CM_ "AUTOGENERATED FILE, DO NOT EDIT"
CM_ "Imported file _honda_2017.dbc starts here"
VERSION ""

NS_ :

BU_: EBCM ADAS PCM EPS VSA SCM BDY XXX EPB EON

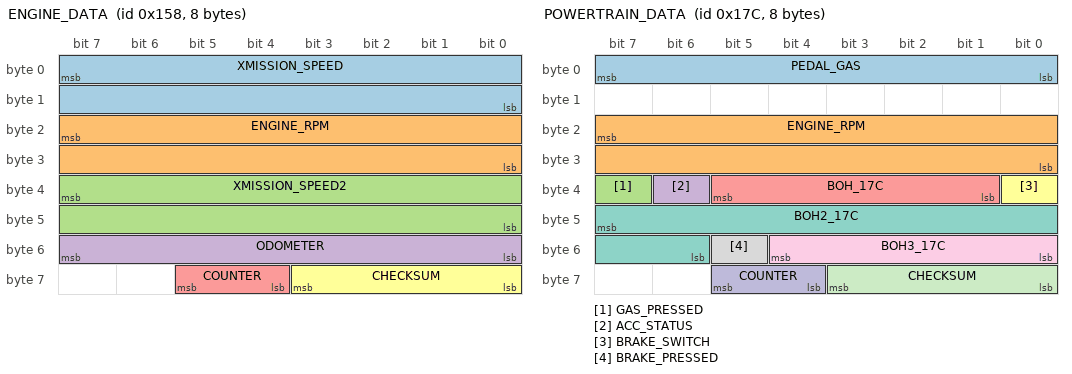
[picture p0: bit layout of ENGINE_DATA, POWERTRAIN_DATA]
BO_ 344 ENGINE_DATA: 8 PCM
 SG_ XMISSION_SPEED : 7|16@0+ (0.01,0) [0|250] "kph" EON
 SG_ ENGINE_RPM : 23|16@0+ (1,0) [0|15000] "rpm" EON
 SG_ XMISSION_SPEED2 : 39|16@0+ (0.01,0) [0|250] "kph" EON
 SG_ ODOMETER : 55|8@0+ (0.010588,0) [0|255] "km" XXX
 SG_ COUNTER : 61|2@0+ (1,0) [0|3] "" EON
 SG_ CHECKSUM : 59|4@0+ (1,0) [0|15] "" EON

BO_ 380 POWERTRAIN_DATA: 8 PCM
 SG_ PEDAL_GAS : 7|8@0+ (1,0) [0|255] "" EON
 SG_ ENGINE_RPM : 23|16@0+ (1,0) [0|15000] "rpm" EON
 SG_ GAS_PRESSED : 39|1@0+ (1,0) [0|1] "" EON
 SG_ ACC_STATUS : 38|1@0+ (1,0) [0|1] "rpm" EON
 SG_ BOH_17C : 37|5@0+ (1,0) [0|1] "rpm" EON
 SG_ BRAKE_SWITCH : 32|1@0+ (1,0) [0|1] "rpm" EON
 SG_ BOH2_17C : 47|10@0+ (1,0) [0|1] "rpm" EON
 SG_ BRAKE_PRESSED : 53|1@0+ (1,0) [0|1] "" EON
 SG_ BOH3_17C : 52|5@0+ (1,0) [0|1] "rpm" EON
 SG_ COUNTER : 61|2@0+ (1,0) [0|3] "" EON
 SG_ CHECKSUM : 59|4@0+ (1,0) [0|15] "" EON

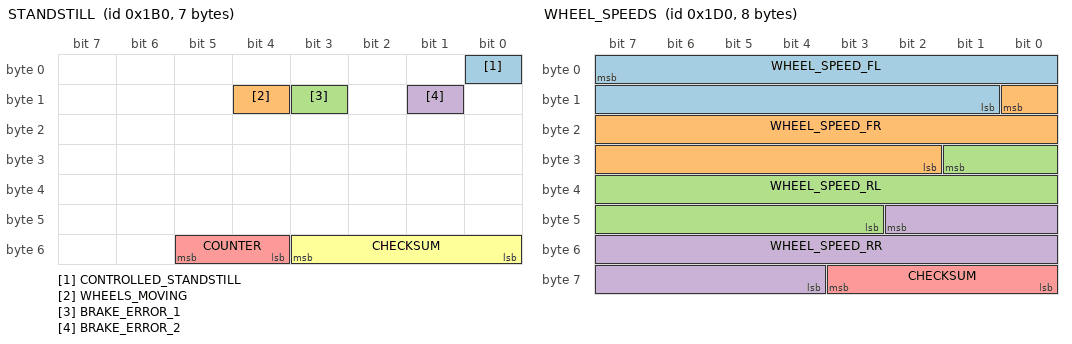
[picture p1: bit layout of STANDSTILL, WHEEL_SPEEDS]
BO_ 432 STANDSTILL: 7 VSA
 SG_ CONTROLLED_STANDSTILL : 0|1@0+ (1,0) [0|1] "" EON
 SG_ WHEELS_MOVING : 12|1@0+ (1,0) [0|1] "" EON
 SG_ BRAKE_ERROR_1 : 11|1@0+ (1,0) [0|1] "" EON
 SG_ BRAKE_ERROR_2 : 9|1@0+ (1,0) [0|1] "" EON
 SG_ COUNTER : 53|2@0+ (1,0) [0|3] "" EON
 SG_ CHECKSUM : 51|4@0+ (1,0) [0|15] "" EON

BO_ 464 WHEEL_SPEEDS: 8 VSA
 SG_ WHEEL_SPEED_FL : 7|15@0+ (0.01,0) [0|250] "kph" EON
 SG_ WHEEL_SPEED_FR : 8|15@0+ (0.01,0) [0|250] "kph" EON
 SG_ WHEEL_SPEED_RL : 25|15@0+ (0.01,0) [0|250] "kph" EON
 SG_ WHEEL_SPEED_RR : 42|15@0+ (0.01,0) [0|250] "kph" EON
 SG_ CHECKSUM : 59|4@0+ (1,0) [0|15] "" EON

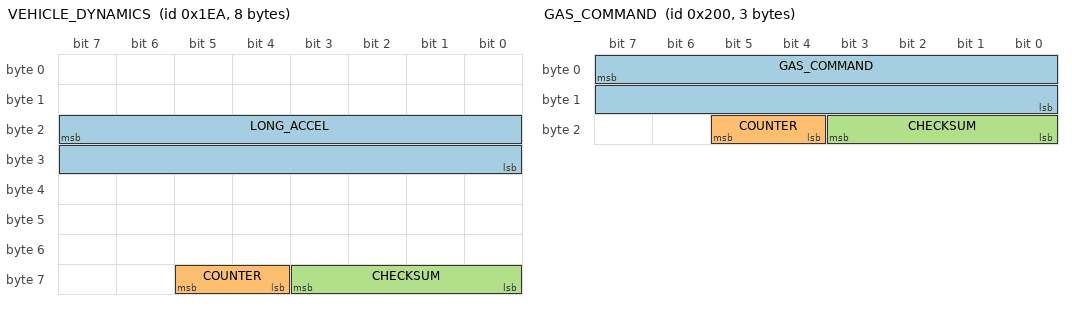
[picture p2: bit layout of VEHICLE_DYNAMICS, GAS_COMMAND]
BO_ 490 VEHICLE_DYNAMICS: 8 VSA
 SG_ LONG_ACCEL : 23|16@0- (0.0015384,0) [-20|20] "m/s2" EON
 SG_ COUNTER : 61|2@0+ (1,0) [0|3] "" EON
 SG_ CHECKSUM : 59|4@0+ (1,0) [0|15] "" EON

BO_ 506 BRAKE_COMMAND: 8 ADAS
 SG_ COMPUTER_BRAKE : 7|10@0+ (1,0) [0|1] "" EBCM
 SG_ ZEROS_BOH : 13|5@0+ (1,0) [0|1] "" EBCM
 SG_ COMPUTER_BRAKE_REQUEST : 8|1@0+ (1,0) [0|1] "" EBCM
 SG_ CRUISE_BOH2 : 23|3@0+ (1,0) [0|1] "" EBCM
 SG_ CRUISE_OVERRIDE : 20|1@0+ (1,0) [0|1] "" EBCM
 SG_ CRUISE_BOH3 : 19|1@0+ (1,0) [0|1] "" EBCM
 SG_ CRUISE_FAULT_CMD : 18|1@0+ (1,0) [0|1] "" EBCM
 SG_ CRUISE_CANCEL_CMD : 17|1@0+ (1,0) [0|1] "" EBCM
 SG_ COMPUTER_BRAKE_REQUEST_2 : 16|1@0+ (1,0) [0|1] "" EBCM
 SG_ SET_ME_0X80 : 31|8@0+ (1,0) [0|1] "" EBCM
 SG_ BRAKE_LIGHTS : 39|1@0+ (1,0) [0|1] "" EBCM
 SG_ CRUISE_STATES : 38|7@0+ (1,0) [0|1] "" EBCM
 SG_ CHIME : 47|3@0+ (1,0) [0|7] "" EBCM
 SG_ ZEROS_BOH6 : 44|1@0+ (1,0) [0|1] "" EBCM
 SG_ FCW : 43|2@0+ (1,0) [0|3] "" EBCM
 SG_ ZEROS_BOH4 : 55|8@0+ (1,0) [0|0] "" EBCM
 SG_ COUNTER : 61|2@0+ (1,0) [0|3] "" EBCM
 SG_ CHECKSUM : 59|4@0+ (1,0) [0|15] "" EBCM

BO_ 512 GAS_COMMAND: 3 EON
 SG_ GAS_COMMAND : 7|16@0+ (1,0) [0|1] "" INTERCEPTOR
 SG_ COUNTER : 21|2@0+ (1,0) [0|3] "" INTERCEPTOR
 SG_ CHECKSUM : 19|4@0+ (1,0) [0|15] "" INTERCEPTOR

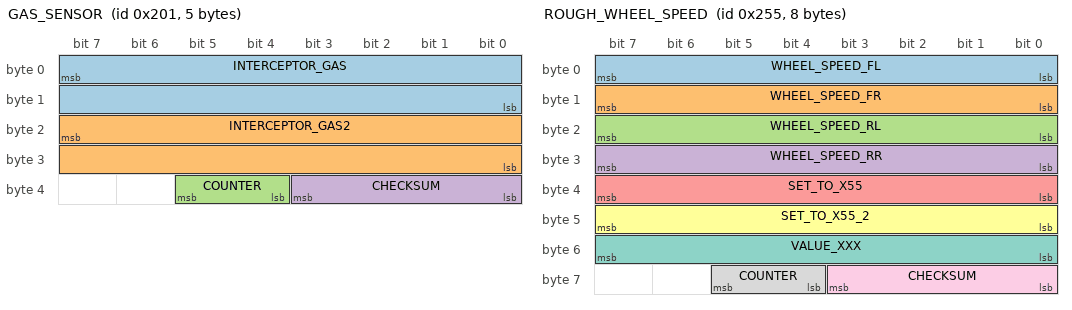
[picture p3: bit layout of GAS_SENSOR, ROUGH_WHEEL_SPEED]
BO_ 513 GAS_SENSOR: 5 INTERCEPTOR
 SG_ INTERCEPTOR_GAS : 7|16@0+ (0.253984064,-83.3) [0|1] "" EON
 SG_ INTERCEPTOR_GAS2 : 23|16@0+ (0.126992032,-83.3) [0|1] "" EON
 SG_ COUNTER : 37|2@0+ (1,0) [0|3] "" EON
 SG_ CHECKSUM : 35|4@0+ (1,0) [0|15] "" EON

BO_ 597 ROUGH_WHEEL_SPEED: 8 VSA
 SG_ WHEEL_SPEED_FL : 7|8@0+ (1,0) [0|255] "mph" EON
 SG_ WHEEL_SPEED_FR : 15|8@0+ (1,0) [0|255] "mph" EON
 SG_ WHEEL_SPEED_RL : 23|8@0+ (1,0) [0|255] "mph" EON
 SG_ WHEEL_SPEED_RR : 31|8@0+ (1,0) [0|255] "mph" EON
 SG_ SET_TO_X55 : 39|8@0+ (1,0) [0|255] "" EON
 SG_ SET_TO_X55_2 : 47|8@0+ (1,0) [0|255] "" EON
 SG_ VALUE_XXX : 55|8@0+ (1,0) [0|255] "" XXX
 SG_ COUNTER : 61|2@0+ (1,0) [0|3] "" EON
 SG_ CHECKSUM : 59|4@0+ (1,0) [0|15] "" EON

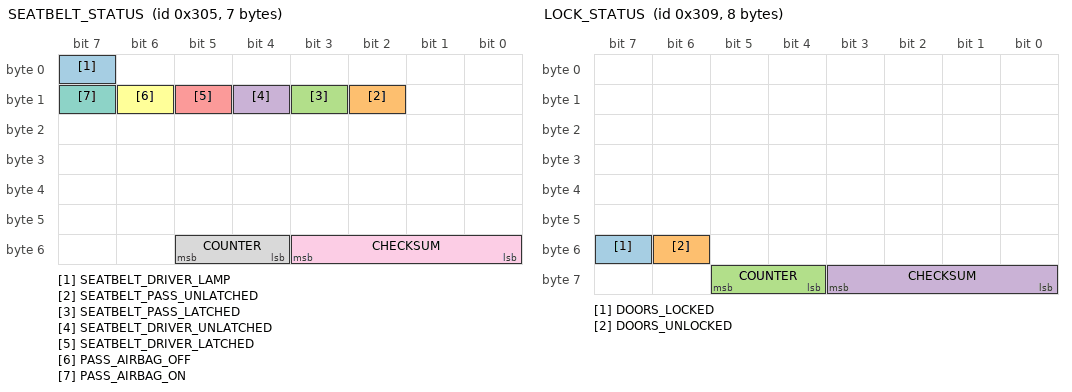
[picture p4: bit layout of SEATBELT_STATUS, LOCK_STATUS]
BO_ 773 SEATBELT_STATUS: 7 BDY
 SG_ SEATBELT_DRIVER_LAMP : 7|1@0+ (1,0) [0|1] "" EON
 SG_ SEATBELT_PASS_UNLATCHED : 10|1@0+ (1,0) [0|1] "" EON
 SG_ SEATBELT_PASS_LATCHED : 11|1@0+ (1,0) [0|1] "" EON
 SG_ SEATBELT_DRIVER_UNLATCHED : 12|1@0+ (1,0) [0|1] "" EON
 SG_ SEATBELT_DRIVER_LATCHED : 13|1@0+ (1,0) [0|1] "" EON
 SG_ PASS_AIRBAG_OFF : 14|1@0+ (1,0) [0|1] "" EON
 SG_ PASS_AIRBAG_ON : 15|1@0+ (1,0) [0|1] "" EON
 SG_ COUNTER : 53|2@0+ (1,0) [0|3] "" EON
 SG_ CHECKSUM : 51|4@0+ (1,0) [0|15] "" EON

BO_ 777 LOCK_STATUS: 8 XXX
 SG_ DOORS_LOCKED : 55|1@0+ (1,0) [0|1] "" EON
 SG_ DOORS_UNLOCKED : 54|1@0+ (1,0) [0|1] "" EON
 SG_ COUNTER : 61|2@0+ (1,0) [0|3] "" EON
 SG_ CHECKSUM : 59|4@0+ (1,0) [0|15] "" EON

BO_ 780 ACC_HUD: 8 ADAS
 SG_ PCM_SPEED : 7|16@0+ (0.01,0) [0|250] "kph" BDY
 SG_ PCM_GAS : 23|8@0+ (1,0) [0|127] "" BDY
 SG_ CRUISE_SPEED : 31|8@0+ (1,0) [0|255] "" BDY
 SG_ DTC_MODE : 39|1@0+ (1,0) [0|1] "" BDY
 SG_ BOH : 38|1@0+ (1,0) [0|1] "" BDY
 SG_ ACC_PROBLEM : 37|1@0+ (1,0) [0|1] "" BDY
 SG_ FCM_OFF : 36|1@0+ (1,0) [0|1] "" BDY
 SG_ BOH_2 : 35|1@0+ (1,0) [0|1] "" BDY
 SG_ FCM_PROBLEM : 34|1@0+ (1,0) [0|1] "" BDY
 SG_ RADAR_OBSTRUCTED : 33|1@0+ (1,0) [0|1] "" BDY
 SG_ ENABLE_MINI_CAR : 32|1@0+ (1,0) [0|1] "" BDY
 SG_ SET_ME_X03 : 47|2@0+ (1,0) [0|3] "" BDY
 SG_ HUD_LEAD : 45|2@0+ (1,0) [0|3] "" BDY
 SG_ BOH_3 : 43|1@0+ (1,0) [0|1] "" BDY
 SG_ BOH_4 : 42|1@0+ (1,0) [0|1] "" BDY
 SG_ BOH_5 : 41|1@0+ (1,0) [0|1] "" BDY
 SG_ CRUISE_CONTROL_LABEL : 40|1@0+ (1,0) [0|3] "" BDY
 SG_ HUD_DISTANCE_3 : 52|1@0+ (1,0) [0|1] "" BDY
 SG_ COUNTER : 61|2@0+ (1,0) [0|3] "" BDY
 SG_ CHECKSUM : 59|4@0+ (1,0) [0|15] "" BDY

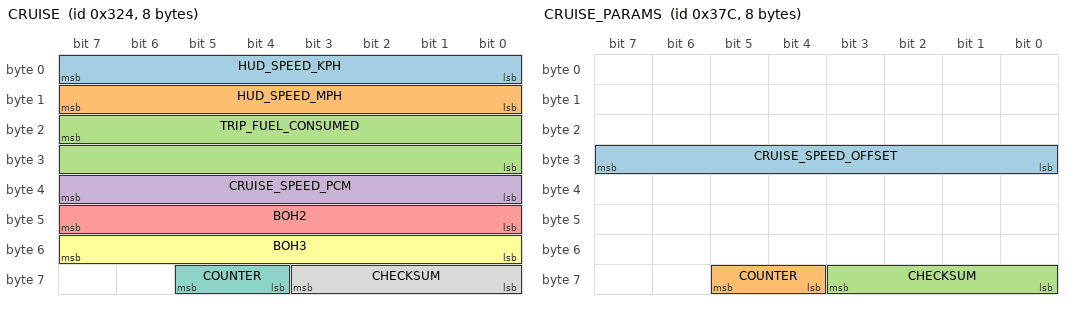
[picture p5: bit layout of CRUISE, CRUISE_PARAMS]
BO_ 804 CRUISE: 8 PCM
 SG_ HUD_SPEED_KPH : 7|8@0+ (1,0) [0|255] "kph" EON
 SG_ HUD_SPEED_MPH : 15|8@0+ (1,0) [0|255] "mph" EON
 SG_ TRIP_FUEL_CONSUMED : 23|16@0+ (1,0) [0|255] "" EON
 SG_ CRUISE_SPEED_PCM : 39|8@0+ (1,0) [0|255] "" EON
 SG_ BOH2 : 47|8@0- (1,0) [0|255] "" EON
 SG_ BOH3 : 55|8@0+ (1,0) [0|255] "" EON
 SG_ COUNTER : 61|2@0+ (1,0) [0|3] "" EON
 SG_ CHECKSUM : 59|4@0+ (1,0) [0|15] "" EON

BO_ 829 LKAS_HUD: 5 ADAS
 SG_ CAM_TEMP_HIGH : 7|1@0+ (1,0) [0|255] "" BDY
 SG_ SET_ME_X41 : 6|7@0+ (1,0) [0|127] "" BDY
 SG_ BOH : 6|7@0+ (1,0) [0|127] "" BDY
 SG_ DASHED_LANES : 14|1@0+ (1,0) [0|1] "" BDY
 SG_ DTC : 13|1@0+ (1,0) [0|1] "" BDY
 SG_ LKAS_PROBLEM : 12|1@0+ (1,0) [0|1] "" BDY
 SG_ LKAS_OFF : 11|1@0+ (1,0) [0|1] "" BDY
 SG_ SOLID_LANES : 10|1@0+ (1,0) [0|1] "" BDY
 SG_ LDW_RIGHT : 9|1@0+ (1,0) [0|1] "" BDY
 SG_ STEERING_REQUIRED : 8|1@0+ (1,0) [0|1] "" BDY
 SG_ BOH : 23|2@0+ (1,0) [0|4] "" BDY
 SG_ LDW_PROBLEM : 21|1@0+ (1,0) [0|1] "" BDY
 SG_ BEEP : 17|2@0+ (1,0) [0|1] "" BDY
 SG_ LDW_ON : 28|1@0+ (1,0) [0|1] "" BDY
 SG_ LDW_OFF : 27|1@0+ (1,0) [0|1] "" BDY
 SG_ CLEAN_WINDSHIELD : 26|1@0+ (1,0) [0|1] "" BDY
 SG_ SET_ME_X48 : 31|8@0+ (1,0) [0|255] "" BDY
 SG_ COUNTER : 37|2@0+ (1,0) [0|3] "" BDY
 SG_ CHECKSUM : 35|4@0+ (1,0) [0|15] "" BDY

BO_ 892 CRUISE_PARAMS: 8 PCM
 SG_ CRUISE_SPEED_OFFSET : 31|8@0- (0.1,0) [-128|127] "kph" EON
 SG_ COUNTER : 61|2@0+ (1,0) [0|3] "" EON
 SG_ CHECKSUM : 59|4@0+ (1,0) [0|15] "" EON

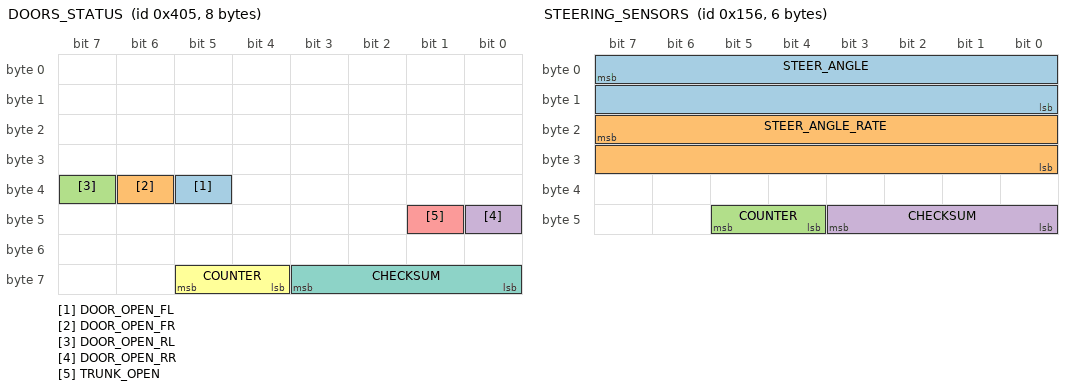
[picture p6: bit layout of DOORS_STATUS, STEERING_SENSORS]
BO_ 1029 DOORS_STATUS: 8 BDY
 SG_ DOOR_OPEN_FL : 37|1@0+ (1,0) [0|1] "" EON
 SG_ DOOR_OPEN_FR : 38|1@0+ (1,0) [0|1] "" EON
 SG_ DOOR_OPEN_RL : 39|1@0+ (1,0) [0|1] "" EON
 SG_ DOOR_OPEN_RR : 40|1@0+ (1,0) [0|1] "" EON
 SG_ TRUNK_OPEN : 41|1@0+ (1,0) [0|1] "" EON
 SG_ COUNTER : 61|2@0+ (1,0) [0|3] "" EON
 SG_ CHECKSUM : 59|4@0+ (1,0) [0|15] "" EON

CM_ SG_ 490 LONG_ACCEL "wheel speed derivative, noisy and zero snapping";
CM_ SG_ 773 PASS_AIRBAG_ON "Might just be indicator light";
CM_ SG_ 773 PASS_AIRBAG_OFF "Might just be indicator light";
CM_ SG_ 780 CRUISE_SPEED "255 = no speed";
CM_ SG_ 804 CRUISE_SPEED_PCM "255 = no speed";
CM_ SG_ 829 BEEP "beeps are pleasant, chimes are for warnngs etc...";

VAL_ 506 FCW 3 "fcw" 2 "fcw" 1 "fcw" 0 "no_fcw" ;
VAL_ 506 CHIME 4 "double_chime" 3 "single_chime" 2 "continuous_chime" 1 "repeating_chime" 0 "no_chime" ;
VAL_ 780 CRUISE_SPEED 255 "no_speed" 252 "stopped" ;
VAL_ 780 HUD_LEAD 3 "acc_off" 2 "solid_car" 1 "dashed_car" 0 "no_car" ;
VAL_ 829 BEEP 3 "single_beep" 2 "triple_beep" 1 "repeated_beep" 0 "no_beep" ;

CM_ "honda_hrv_exl_2016_can.dbc starts here"

BO_ 57 XXX_1: 3 XXX
 SG_ CHECKSUM : 19|4@0+ (1,0) [0|15] "" EON
 SG_ COUNTER : 21|2@0+ (1,0) [0|3] "" EON

BO_ 145 XXX_2: 8 XXX
 SG_ COUNTER : 61|2@0+ (1,0) [0|3] "" EON
 SG_ CHECKSUM : 59|4@0+ (1,0) [0|15] "" EON

BO_ 316 XXX_3: 8 XXX
 SG_ COUNTER : 61|2@0+ (1,0) [0|3] "" EON
 SG_ CHECKSUM : 59|4@0+ (1,0) [0|15] "" EON

BO_ 340 XXX_4: 8 XXX
 SG_ COUNTER : 61|2@0+ (1,0) [0|3] "" EON
 SG_ CHECKSUM : 59|4@0+ (1,0) [0|15] "" EON

BO_ 342 STEERING_SENSORS: 6 EPS
 SG_ STEER_ANGLE : 7|16@0- (-0.1,0) [-500|500] "deg" EON
 SG_ STEER_ANGLE_RATE : 23|16@0- (1,0) [-3000|3000] "deg/s" EON
 SG_ COUNTER : 45|2@0+ (1,0) [0|3] "" EON
 SG_ CHECKSUM : 43|4@0+ (1,0) [0|15] "" EON

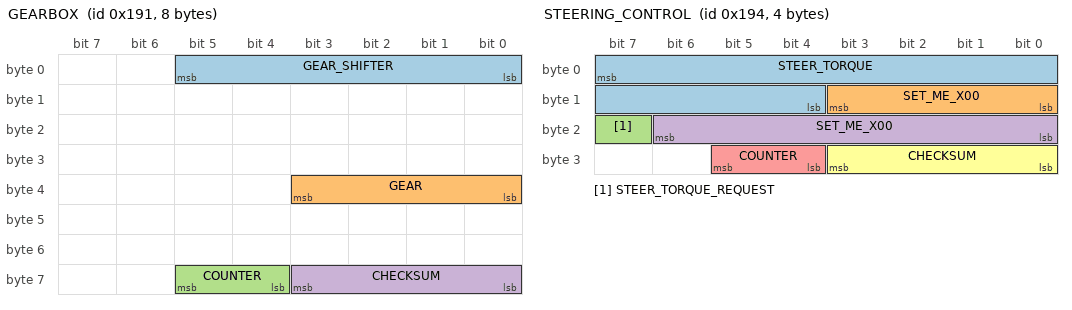
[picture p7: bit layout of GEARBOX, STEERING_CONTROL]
BO_ 401 GEARBOX: 8 PCM
 SG_ GEAR_SHIFTER : 5|6@0+ (1,0) [0|63] ""  EON
 SG_ GEAR : 35|4@0+ (1,0) [0|15] ""  EON
 SG_ COUNTER : 61|2@0+ (1,0) [0|3] ""  EON
 SG_ CHECKSUM : 59|4@0+ (1,0) [0|15] ""  EON

BO_ 404 STEERING_CONTROL: 4 EON
 SG_ STEER_TORQUE : 7|12@0- (1,0) [-768|768] "" EPS
 SG_ SET_ME_X00 : 11|4@0+ (1,0) [0|15] "" EPS
 SG_ STEER_TORQUE_REQUEST : 23|1@0+ (1,0) [0|1] "" EPS
 SG_ SET_ME_X00 : 22|7@0+ (1,0) [0|127] "" EPS
 SG_ COUNTER : 29|2@0+ (1,0) [0|15] "" EPS
 SG_ CHECKSUM : 27|4@0+ (1,0) [0|3] "" EPS

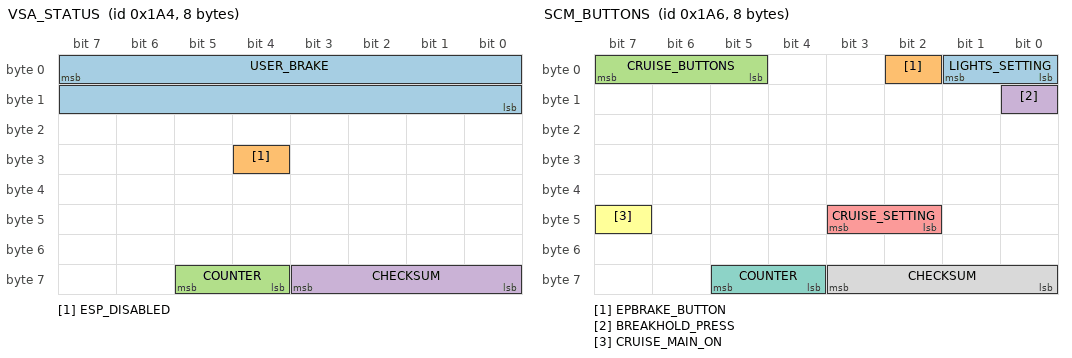
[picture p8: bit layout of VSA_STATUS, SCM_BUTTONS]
BO_ 420 VSA_STATUS: 8 VSA
 SG_ USER_BRAKE : 7|16@0+ (0.015625,-1.609375) [0|1000] "" EON
 SG_ ESP_DISABLED : 28|1@0+ (1,0) [0|1] "" EON
 SG_ COUNTER : 61|2@0+ (1,0) [0|3] "" EON
 SG_ CHECKSUM : 59|4@0+ (1,0) [0|15] "" EON

BO_ 422 SCM_BUTTONS: 8 SCM
 SG_ LIGHTS_SETTING : 1|2@0+ (1,0) [0|3] "" EON
 SG_ EPBRAKE_BUTTON : 2|1@0+ (1,0) [0|1] "" EON
 SG_ CRUISE_BUTTONS : 7|3@0+ (1,0) [0|7] "" EON
 SG_ BREAKHOLD_PRESS : 8|1@0+ (1,0) [0|1] "" EON
 SG_ CRUISE_SETTING : 43|2@0+ (1,0) [0|3] "" EON
 SG_ CRUISE_MAIN_ON : 47|1@0+ (1,0) [0|1] "" EON
 SG_ COUNTER : 61|2@0+ (1,0) [0|3] "" EON
 SG_ CHECKSUM : 59|4@0+ (1,0) [0|15] "" EON

BO_ 423 XXX_5: 2 XXX
 SG_ COUNTER : 13|2@0+ (1,0) [0|3] "" EON
 SG_ CHECKSUM : 11|4@0+ (1,0) [0|15] "" EON

BO_ 426 XXX_6: 8 XXX
 SG_ COUNTER : 61|2@0+ (1,0) [0|3] "" EON
 SG_ CHECKSUM : 59|4@0+ (1,0) [0|15] "" EON

BO_ 427 XXX_7: 3 XXX
 SG_ COUNTER : 21|2@0+ (1,0) [0|3] "" EON
 SG_ CHECKSUM : 19|4@0+ (1,0) [0|15] "" EON

BO_ 441 XXX_8: 5 XXX
 SG_ COUNTER : 37|2@0+ (1,0) [0|3] "" EON
 SG_ CHECKSUM : 35|4@0+ (1,0) [0|15] "" EON

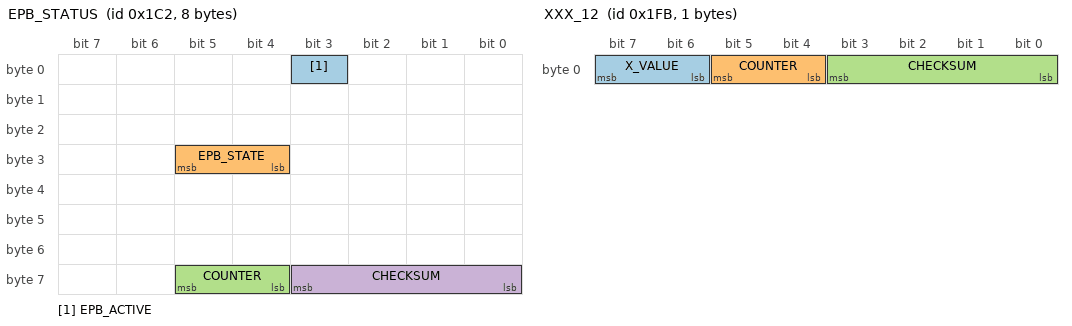
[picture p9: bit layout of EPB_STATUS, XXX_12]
BO_ 450 EPB_STATUS: 8 EPB
 SG_ EPB_ACTIVE : 3|1@0+ (1,0) [0|1] "" EON
 SG_ EPB_STATE : 29|2@0+ (1,0) [0|3] "" EON
 SG_ COUNTER : 61|2@0+ (1,0) [0|3] "" EON
 SG_ CHECKSUM : 59|4@0+ (1,0) [0|15] "" EON

BO_ 474 XXX_9: 5 XXX
 SG_ COUNTER : 37|2@0+ (1,0) [0|3] "" EON
 SG_ CHECKSUM : 35|4@0+ (1,0) [0|15] "" EON

BO_ 476 XXX_10: 7 XXX
 SG_ COUNTER : 53|2@0+ (1,0) [0|3] "" EON
 SG_ CHECKSUM : 51|4@0+ (1,0) [0|15] "" EON

BO_ 493 XXX_11: 3 XXX
 SG_ COUNTER : 21|2@0+ (1,0) [0|3] "" EON
 SG_ CHECKSUM : 19|4@0+ (1,0) [0|15] "" EON

BO_ 507 XXX_12: 1 XXX
 SG_ X_VALUE : 7|2@0+ (1,0) [0|3] "" XXX
 SG_ COUNTER : 5|2@0+ (1,0) [0|3] "" EON
 SG_ CHECKSUM : 3|4@0+ (1,0) [0|15] "" EON

BO_ 545 xxx_13: 4 XXX
 SG_ COUNTER : 29|2@0+ (1,0) [0|3] "" EON
 SG_ CHECKSUM : 27|4@0+ (1,0) [0|15] "" EON

BO_ 578 XXX_14: 2 XXX
 SG_ COUNTER : 13|2@0+ (1,0) [0|3] "" EON
 SG_ CHECKSUM : 11|4@0+ (1,0) [0|15] "" EON

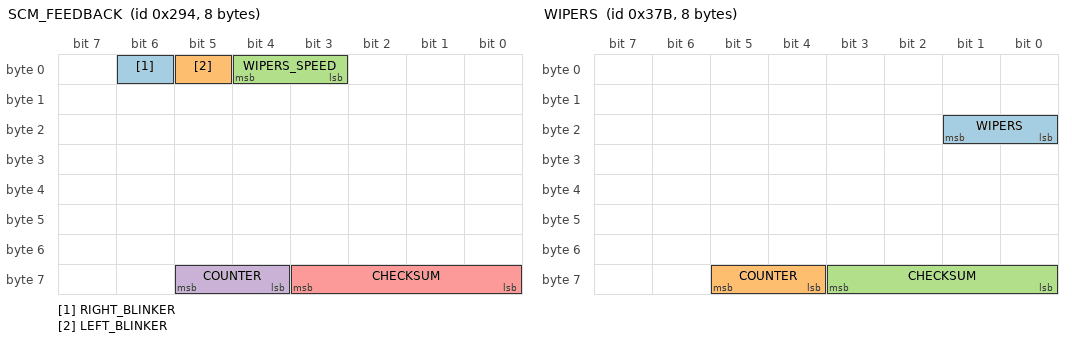
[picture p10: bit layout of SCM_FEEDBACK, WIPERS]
BO_ 660 SCM_FEEDBACK: 8 SCM
 SG_ RIGHT_BLINKER : 6|1@0+ (1,0) [0|1] "" EON
 SG_ LEFT_BLINKER : 5|1@0+ (1,0) [0|1] "" EON
 SG_ WIPERS_SPEED : 4|2@0+ (1,0) [0|3] "" EON
 SG_ COUNTER : 61|2@0+ (1,0) [0|3] "" EON
 SG_ CHECKSUM : 59|4@0+ (1,0) [0|15] "" EON

BO_ 661 XXX_15: 4 XXX
 SG_ COUNTER : 29|2@0+ (1,0) [0|3] "" XXX
 SG_ CHECKSUM : 27|4@0+ (1,0) [0|15] "" XXX

BO_ 800 MSGID_800: 8 XXX
 SG_ COUNTER : 61|2@0+ (1,0) [0|3] "" XXX
 SG_ CHECKSUM : 59|4@0+ (1,0) [0|15] "" XXX

BO_ 808 MSGID_808: 8 XXX
 SG_ COUNTER : 61|2@0+ (1,0) [0|3] "" XXX
 SG_ CHECKSUM : 59|4@0+ (1,0) [0|15] "" XXX

BO_ 882 MSGID_882: 2 XXX
 SG_ COUNTER : 13|2@0+ (1,0) [0|3] "" XXX
 SG_ CHECKSUM : 11|4@0+ (1,0) [0|15] "" XXX

BO_ 884 MSGID_884: 7 XXX
 SG_ COUNTER : 53|2@0+ (1,0) [0|3] "" EON
 SG_ CHECKSUM : 51|4@0+ (1,0) [0|15] "" EON

BO_ 891 WIPERS: 8 XXX
 SG_ WIPERS : 17|2@0+ (1,0) [0|3] "" EON
 SG_ COUNTER : 61|2@0+ (1,0) [0|3] "" EON
 SG_ CHECKSUM : 59|4@0+ (1,0) [0|3] "" EON

BO_ 918 MSGID_918: 7 XXX
 SG_ COUNTER : 53|2@0+ (1,0) [0|3] "" XXX
 SG_ CHECKSUM : 51|4@0+ (1,0) [0|15] "" XXX

BO_ 983 MSGID_983: 8 XXX
 SG_ COUNTER : 61|2@0+ (1,0) [0|3] "" XXX
 SG_ CHECKSUM : 59|4@0+ (1,0) [0|15] "" XXX

BO_ 985 MSGID_985: 3 XXX
 SG_ COUNTER : 21|2@0+ (1,0) [0|15] "" XXX
 SG_ CHECKSUM : 19|4@0+ (1,0) [0|3] "" XXX

BO_ 1024 MSGID_1024: 5 XXX
 SG_ COUNTER : 37|2@0+ (1,0) [0|3] "" EON
 SG_ CHECKSUM : 35|4@0+ (1,0) [0|15] "" EON

BO_ 1027 MSGID_1027: 5 XXX
 SG_ COUNTER : 37|2@0+ (1,0) [0|3] "" XXX
 SG_ CHECKSUM : 35|4@0+ (1,0) [0|15] "" XXX

BO_ 1030 MSGID_1030: 5 XXX
 SG_ COUNTER : 37|2@0+ (1,0) [0|3] "" XXX
 SG_ CHECKSUM : 35|4@0+ (1,0) [0|15] "" XXX

BO_ 1033 MSGID_1033: 5 XXX
 SG_ COUNTER : 37|2@0+ (1,0) [0|3] "" XXX
 SG_ CHECKSUM : 35|4@0+ (1,0) [0|15] "" XXX

BO_ 1036 MSGID_1036: 8 XXX
 SG_ COUNTER : 61|2@0+ (1,0) [0|3] "" XXX
 SG_ CHECKSUM : 59|4@0+ (1,0) [0|15] "" XXX

BO_ 1039 MSGID_1039: 8 XXX
 SG_ COUNTER : 61|2@0+ (1,0) [0|3] "" XXX
 SG_ CHECKSUM : 59|4@0+ (1,0) [0|15] "" XXX

BO_ 1064 MSGID_1064: 7 XXX
 SG_ COUNTER : 53|2@0+ (1,0) [0|3] "" XXX
 SG_ CHECKSUM : 51|4@0+ (1,0) [0|15] "" XXX

BO_ 1108 MSGID_1108: 8 XXX
 SG_ COUNTER : 61|2@0+ (1,0) [0|3] "" XXX
 SG_ CHECKSUM : 59|4@0+ (1,0) [0|15] "" XXX

BO_ 1115 MSGID_1115: 2 XXX
 SG_ COUNTER : 13|2@0+ (1,0) [0|3] "" XXX
 SG_ CHECKSUM : 11|4@0+ (1,0) [0|15] "" XXX

BO_ 1125 MSGID_1125: 8 XXX
 SG_ COUNTER : 61|2@0+ (1,0) [0|3] "" XXX
 SG_ CHECKSUM : 59|4@0+ (1,0) [0|15] "" XXX

BO_ 1137 MSGID_1137: 8 XXX
 SG_ COUNTER : 61|2@0+ (1,0) [0|3] "" XXX
 SG_ CHECKSUM : 59|4@0+ (1,0) [0|15] "" XXX

BO_ 1296 MSGID_1296: 8 XXX
 SG_ COUNTER : 61|2@0+ (1,0) [0|3] "" XXX
 SG_ CHECKSUM : 59|4@0+ (1,0) [0|15] "" XXX

BO_ 1348 MSGID_1348: 5 XXX
 SG_ COUNTER : 37|2@0+ (1,0) [0|3] "" XXX
 SG_ CHECKSUM : 35|4@0+ (1,0) [0|15] "" XXX

BO_ 1361 MSGID_1361: 5 XXX
 SG_ COUNTER : 37|2@0+ (1,0) [0|3] "" XXX
 SG_ CHECKSUM : 35|4@0+ (1,0) [0|15] "" XXX

BO_ 1365 MSGID_1365: 5 XXX
 SG_ COUNTER : 37|2@0+ (1,0) [0|3] "" XXX
 SG_ CHECKSUM : 35|4@0+ (1,0) [0|15] "" XXX

CM_ SG_ 401 GEAR "10 = reverse, 11 = transition";
CM_ SG_ 450 EPB_STATE "3: On, 2: Disengaging, 1: Engaging, 0: Off";

VAL_ 399 STEER_STATUS 5 "fault" 4 "no_torque_alert_2" 2 "no_torque_alert_1" 0 "normal" ;
VAL_ 401 GEAR_SHIFTER 32 "L" 16 "S" 8 "D" 4 "N" 2 "R" 1 "P" ;
VAL_ 401 GEAR 7 "L" 10 "S" 4 "D" 3 "N" 2 "R" 1 "P" ;
VAL_ 422 CRUISE_BUTTONS 7 "tbd" 6 "tbd" 5 "tbd" 4 "accel_res" 3 "decel_set" 2 "cancel" 1 "main" 0 "none" ;
VAL_ 422 LIGHTS_SETTING 3 "high_beam" 2 "low_beam" 1 "position" 0 "no_lights" ;
VAL_ 422 CRUISE_SETTING 3 "distance_adj" 2 "tbd" 1 "lkas_button" 0 "none" ;
VAL_ 450 EPB_STATE 3 "on" 2 "disengaging" 1 "engaging" 0 "off" ;
VAL_ 660 WIPERS_SPEED 3 "high" 2 "low" 1 "intermittent" 0 "off" ;
VAL_ 891 WIPERS 2 "High" 1 "Low" 0 "Off" ;

CM_ "CHFFR_METRIC 342 STEER_ANGLE STEER_ANGLE 0.36 180; CHFFR_METRIC 380 ENGINE_RPM ENGINE_RPM 1 0; CHFFR_METRIC 804 ENGINE_TEMPERATURE ENGINE_TEMPERATURE 1 0";
